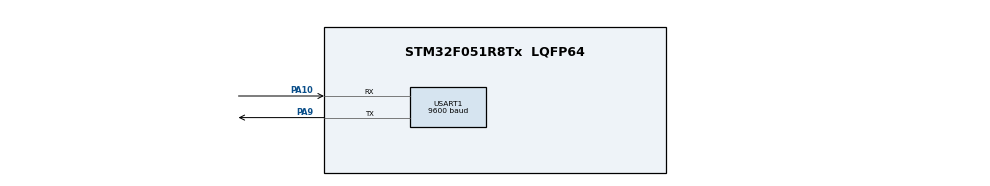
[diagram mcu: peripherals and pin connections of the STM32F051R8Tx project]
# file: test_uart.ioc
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Mcu.Family=STM32F0
Mcu.Name=STM32F051R8Tx
Mcu.Package=LQFP64
NVIC.USART1_IRQn=true\:0\:0\:false\:false\:true\:true\:true\:true
PA10.Mode=Asynchronous
PA10.Signal=USART1_RX
PA9.Mode=Asynchronous
PA9.Signal=USART1_TX
ProjectManager.HeapSize=0x200
ProjectManager.StackSize=0x400
ProjectManager.TargetToolchain=STM32CubeIDE
USART1.BaudRate=9600
USART1.VirtualMode-Asynchronous=VM_ASYNC
board=custom

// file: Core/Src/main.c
/* USER CODE BEGIN Header */
/**
  ******************************************************************************
  * @file           : main.c
  * @brief          : Main program body
  ******************************************************************************
  * @attention
  *
  * Copyright (c) 2023 STMicroelectronics.
  * All rights reserved.
  *
  * This software is licensed under terms that can be found in the LICENSE file
  * in the root directory of this software component.
  * If no LICENSE file comes with this software, it is provided AS-IS.
  *
  ******************************************************************************
  */
/* USER CODE END Header */
#include "main.h"
#include "stdio.h"

UART_HandleTypeDef huart1;

/* Define variables to send */
int i = 0;
char buffer[100];
int len;

/* Define variables to receive */
char Rx_indx, Rx_data[2], Rx_Buffer[100], Transfer_cplt;

void SystemClock_Config(void);
static void MX_GPIO_Init(void);
static void MX_USART1_UART_Init(void);

/* USER CODE BEGIN 0 */
/* Private function prototypes -----------------------------------------------*/
#ifdef __GNUC__
  /* With GCC/RAISONANCE, small printf (option LD Linker->Libraries->Small printf
     set to 'Yes') calls __io_putchar() */
  #define PUTCHAR_PROTOTYPE int __io_putchar(int ch)
#else
  #define PUTCHAR_PROTOTYPE int fputc(int ch, FILE *f)
#endif /* __GNUC__ */

/**
  * @brief  Retargets the C library printf function to the USART.
  * @param  None
  * @retval None
  */
PUTCHAR_PROTOTYPE
{
    /* Place your implementation of fputc here */
    /* e.g. write a character to the USART */
    HAL_UART_Transmit(&huart1, (uint8_t *)&ch, 1, 100);

    return ch;
}
/* USER CODE END 0 */

/* USER CODE BEGIN 1 */
//Interrupt callback routine
void HAL_UART_RxCpltCallback(UART_HandleTypeDef *huart)
{
    uint8_t i;
    if (huart->Instance == USART1)  //current UART
        {
        if (Rx_indx==0) {for (i=0;i<100;i++) Rx_Buffer[i]=0;}   //clear Rx_Buffer before receiving new data

        if (Rx_data[0]!=13) //if received data different from ascii 13 (enter)
            {
            Rx_Buffer[Rx_indx++]=Rx_data[0];    //add data to Rx_Buffer
            }
        else            //if received data = 13
            {
            Rx_indx=0;
            Transfer_cplt=1;//transfer complete, data is ready to read
            }

        HAL_UART_Receive_IT(&huart1, Rx_data, 1);   //activate UART receive interrupt every time
        }
}
/* USER CODE END 1 */

int main(void)
{

  /* MCU Configuration--------------------------------------------------------*/

  /* Reset of all peripherals, Initializes the Flash interface and the Systick. */
  HAL_Init();

  /* Configure the system clock */
  SystemClock_Config();

  /* Initialize all configured peripherals */
  MX_GPIO_Init();
  MX_USART1_UART_Init();
  /* USER CODE BEGIN 2 */
  HAL_UART_Receive_IT(&huart1, Rx_data, 1); // active uart rx intterupt every time receiving 1 byte

  /* USER CODE END 2 */

  /* Infinite loop */
  /* USER CODE BEGIN WHILE */
  while (1)
  {
	  /* Case send data */
#if 0
	  //For sending data out in while(1)
	  printf("Hello Nguyen Thanh Dinh\r\n");
	  HAL_Delay(500);
	  printf("This is i:%i\r\n",i);
	  i++;

	  //print out static text
	  sprintf(buffer,"Hello\r\n");
	  len=strlen(buffer);
	  HAL_UART_Transmit(&huart1, buffer, len, 1000);
	  HAL_Delay(500);

	  //print out variable
	  sprintf(buffer,"This is i:%i\r\n",i);
	  len=strlen(buffer);
	  HAL_UART_Transmit(&huart1, buffer, len, 1000);
	  i++;
#endif

	  /* Case receive data and send data */
#if 1
	  if (Transfer_cplt){
		  //print out static text
		  sprintf(buffer,"%s\r\n",Rx_Buffer);
		  len=strlen(buffer);
		  HAL_UART_Transmit(&huart1, buffer, len, 1000);
		  Transfer_cplt = 0; // reset complete variable
		  HAL_Delay(500);
	  }
#endif
    /* USER CODE END WHILE */

  }
}

void SystemClock_Config(void)
{
  RCC_OscInitTypeDef RCC_OscInitStruct = {0};
  RCC_ClkInitTypeDef RCC_ClkInitStruct = {0};
  RCC_PeriphCLKInitTypeDef PeriphClkInit = {0};

  /** Initializes the RCC Oscillators according to the specified parameters
  * in the RCC_OscInitTypeDef structure.
  */
  RCC_OscInitStruct.OscillatorType = RCC_OSCILLATORTYPE_HSI;
  RCC_OscInitStruct.HSIState = RCC_HSI_ON;
  RCC_OscInitStruct.HSICalibrationValue = RCC_HSICALIBRATION_DEFAULT;
  RCC_OscInitStruct.PLL.PLLState = RCC_PLL_NONE;
  if (HAL_RCC_OscConfig(&RCC_OscInitStruct) != HAL_OK)
  {
    Error_Handler();
  }

  /** Initializes the CPU, AHB and APB buses clocks
  */
  RCC_ClkInitStruct.ClockType = RCC_CLOCKTYPE_HCLK|RCC_CLOCKTYPE_SYSCLK
                              |RCC_CLOCKTYPE_PCLK1;
  RCC_ClkInitStruct.SYSCLKSource = RCC_SYSCLKSOURCE_HSI;
  RCC_ClkInitStruct.AHBCLKDivider = RCC_SYSCLK_DIV1;
  RCC_ClkInitStruct.APB1CLKDivider = RCC_HCLK_DIV1;

  if (HAL_RCC_ClockConfig(&RCC_ClkInitStruct, FLASH_LATENCY_0) != HAL_OK)
  {
    Error_Handler();
  }
  PeriphClkInit.PeriphClockSelection = RCC_PERIPHCLK_USART1;
  PeriphClkInit.Usart1ClockSelection = RCC_USART1CLKSOURCE_PCLK1;
  if (HAL_RCCEx_PeriphCLKConfig(&PeriphClkInit) != HAL_OK)
  {
    Error_Handler();
  }
}

static void MX_USART1_UART_Init(void)
{

  huart1.Instance = USART1;
  huart1.Init.BaudRate = 9600;
  huart1.Init.WordLength = UART_WORDLENGTH_8B;
  huart1.Init.StopBits = UART_STOPBITS_1;
  huart1.Init.Parity = UART_PARITY_NONE;
  huart1.Init.Mode = UART_MODE_TX_RX;
  huart1.Init.HwFlowCtl = UART_HWCONTROL_NONE;
  huart1.Init.OverSampling = UART_OVERSAMPLING_16;
  huart1.Init.OneBitSampling = UART_ONE_BIT_SAMPLE_DISABLE;
  huart1.AdvancedInit.AdvFeatureInit = UART_ADVFEATURE_NO_INIT;
  if (HAL_UART_Init(&huart1) != HAL_OK)
  {
    Error_Handler();
  }

}

static void MX_GPIO_Init(void)
{

  /* GPIO Ports Clock Enable */
  __HAL_RCC_GPIOA_CLK_ENABLE();

}

void Error_Handler(void)
{
  __disable_irq();
  while (1)
  {
  }
}
